# COMPUTE_CLUSTER0_MSMC_ECC_AGGR1_MSMC_ECC_AGGR1 register map
Vendor: Texas Instruments
Peripheral module from a debugger description file (folder J721S2).
Registers are 32-bit, access not given, reset 0x0 unless marked. A register's access mark holds for its fields unless they carry their own. Offsets are as the file gives them; lines under a group give offsets from that group; [hi:lo] are bit positions; {n}, {i} and the like mark numbered series; 'fields as' and 'values as' point back to an identical list; <NAME> marks a mode.

## COMPUTE_CLUSTER0_MSMC_ECC_AGGR1_MSMC_ECC_AGGR1
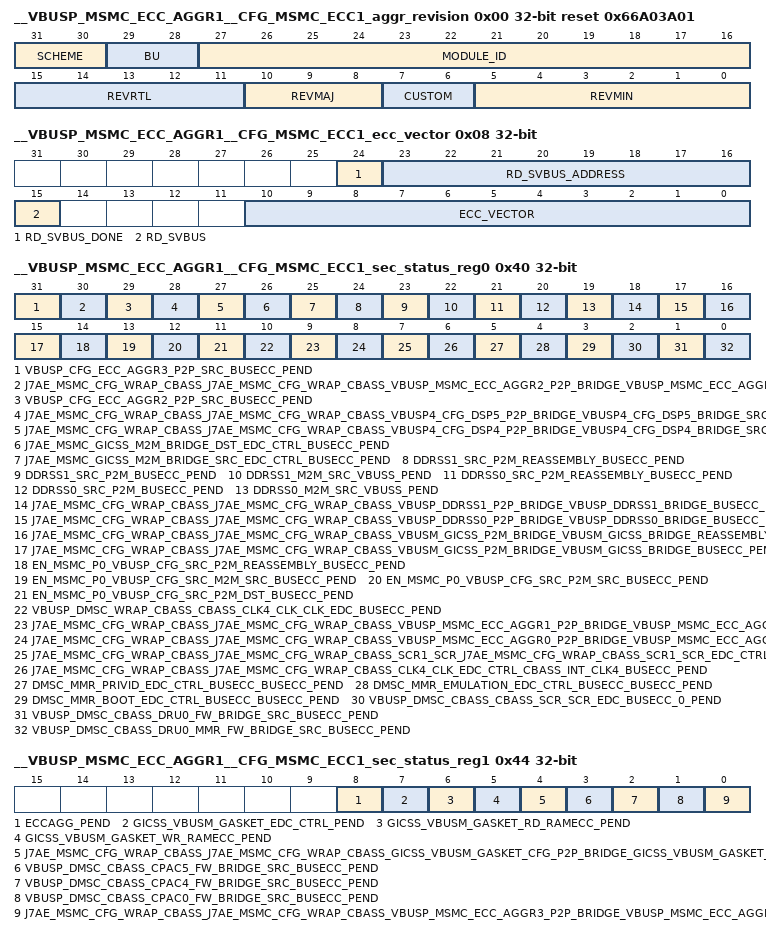
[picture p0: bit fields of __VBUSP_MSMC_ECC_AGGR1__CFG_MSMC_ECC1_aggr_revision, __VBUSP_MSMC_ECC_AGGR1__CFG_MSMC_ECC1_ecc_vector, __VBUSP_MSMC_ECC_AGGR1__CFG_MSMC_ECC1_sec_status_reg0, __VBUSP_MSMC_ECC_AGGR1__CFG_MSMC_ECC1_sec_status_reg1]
0x00 __VBUSP_MSMC_ECC_AGGR1__CFG_MSMC_ECC1_aggr_revision ro reset 0x66A03A01 — Revision parameters
  [31:30] SCHEME
  [29:28] BU
  [27:16] MODULE_ID
  [15:11] REVRTL — RTL version
  [10:8] REVMAJ — Major version
  [7:6] CUSTOM — Custom version
  [5:0] REVMIN — Minor version
0x08 __VBUSP_MSMC_ECC_AGGR1__CFG_MSMC_ECC1_ecc_vector — ECC Vector Register
  [24] RD_SVBUS_DONE — Status to indicate if read on serial VBUS is complete, write of any value will clear this bit. (access R/W1TC)
  [23:16] RD_SVBUS_ADDRESS rw — Read address
  [15] RD_SVBUS — Write 1 to trigger a read on the serial VBUS (access R/W1TS)
  [10:0] ECC_VECTOR rw — Value written to select the corresponding ECC RAM for control or status
0x0C __VBUSP_MSMC_ECC_AGGR1__CFG_MSMC_ECC1_misc_status ro reset 0x29 — Misc Status
  [10:0] NUM_RAMS — Indicates the number of RAMS serviced by the ECC aggregator
0x10 __VBUSP_MSMC_ECC_AGGR1__CFG_MSMC_ECC1_reserved_svbus rw — Reference other documents that contain the ECC RAM wrapper and EDC controller serial vbus register sets.
  [31:0] DATA — Serial VBUS register data
0x3C __VBUSP_MSMC_ECC_AGGR1__CFG_MSMC_ECC1_sec_eoi_reg — EOI Register
  [0] EOI_WR — EOI Register (access R/W1TS)
0x40 __VBUSP_MSMC_ECC_AGGR1__CFG_MSMC_ECC1_sec_status_reg0 — Interrupt Status Register 0
  [31] VBUSP_CFG_ECC_AGGR3_P2P_SRC_BUSECC_PEND — Interrupt Pending Status for vbusp_cfg_ecc_aggr3_p2p_src_busecc_pend (access R/W1TS)
  [30] J7AE_MSMC_CFG_WRAP_CBASS_J7AE_MSMC_CFG_WRAP_CBASS_VBUSP_MSMC_ECC_AGGR2_P2P_BRIDGE_VBUSP_MSMC_ECC_AGGR2_BRIDGE_BUSECC_PEND — Interrupt Pending Status for j7ae_msmc_cfg_wrap_cbass_j7ae_msmc_cfg_wrap_cbass_vbusp_msmc_ecc_aggr2_p2p_bridge_vbusp_msmc_ecc_aggr2_bridge_busecc_pend (access R/W1TS)
  [29] VBUSP_CFG_ECC_AGGR2_P2P_SRC_BUSECC_PEND — Interrupt Pending Status for vbusp_cfg_ecc_aggr2_p2p_src_busecc_pend (access R/W1TS)
  [28] J7AE_MSMC_CFG_WRAP_CBASS_J7AE_MSMC_CFG_WRAP_CBASS_VBUSP4_CFG_DSP5_P2P_BRIDGE_VBUSP4_CFG_DSP5_BRIDGE_SRC_BUSECC_PEND — Interrupt Pending Status for j7ae_msmc_cfg_wrap_cbass_j7ae_msmc_cfg_wrap_cbass_vbusp4_cfg_dsp5_p2p_bridge_vbusp4_cfg_dsp5_bridge_src_busecc_pend (access R/W1TS)
  [27] J7AE_MSMC_CFG_WRAP_CBASS_J7AE_MSMC_CFG_WRAP_CBASS_VBUSP4_CFG_DSP4_P2P_BRIDGE_VBUSP4_CFG_DSP4_BRIDGE_SRC_BUSECC_PEND — Interrupt Pending Status for j7ae_msmc_cfg_wrap_cbass_j7ae_msmc_cfg_wrap_cbass_vbusp4_cfg_dsp4_p2p_bridge_vbusp4_cfg_dsp4_bridge_src_busecc_pend (access R/W1TS)
  [26] J7AE_MSMC_GICSS_M2M_BRIDGE_DST_EDC_CTRL_BUSECC_PEND — Interrupt Pending Status for j7ae_msmc_gicss_m2m_bridge_dst_edc_ctrl_busecc_pend (access R/W1TS)
  [25] J7AE_MSMC_GICSS_M2M_BRIDGE_SRC_EDC_CTRL_BUSECC_PEND — Interrupt Pending Status for j7ae_msmc_gicss_m2m_bridge_src_edc_ctrl_busecc_pend (access R/W1TS)
  [24] DDRSS1_SRC_P2M_REASSEMBLY_BUSECC_PEND — Interrupt Pending Status for ddrss1_src_p2m_reassembly_busecc_pend (access R/W1TS)
  [23] DDRSS1_SRC_P2M_BUSECC_PEND — Interrupt Pending Status for ddrss1_src_p2m_busecc_pend (access R/W1TS)
  [22] DDRSS1_M2M_SRC_VBUSS_PEND — Interrupt Pending Status for ddrss1_m2m_src_vbuss_pend (access R/W1TS)
  [21] DDRSS0_SRC_P2M_REASSEMBLY_BUSECC_PEND — Interrupt Pending Status for ddrss0_src_p2m_reassembly_busecc_pend (access R/W1TS)
  [20] DDRSS0_SRC_P2M_BUSECC_PEND — Interrupt Pending Status for ddrss0_src_p2m_busecc_pend (access R/W1TS)
  [19] DDRSS0_M2M_SRC_VBUSS_PEND — Interrupt Pending Status for ddrss0_m2m_src_vbuss_pend (access R/W1TS)
  [18] J7AE_MSMC_CFG_WRAP_CBASS_J7AE_MSMC_CFG_WRAP_CBASS_VBUSP_DDRSS1_P2P_BRIDGE_VBUSP_DDRSS1_BRIDGE_BUSECC_PEND — Interrupt Pending Status for j7ae_msmc_cfg_wrap_cbass_j7ae_msmc_cfg_wrap_cbass_vbusp_ddrss1_p2p_bridge_vbusp_ddrss1_bridge_busecc_pend (access R/W1TS)
  [17] J7AE_MSMC_CFG_WRAP_CBASS_J7AE_MSMC_CFG_WRAP_CBASS_VBUSP_DDRSS0_P2P_BRIDGE_VBUSP_DDRSS0_BRIDGE_BUSECC_PEND — Interrupt Pending Status for j7ae_msmc_cfg_wrap_cbass_j7ae_msmc_cfg_wrap_cbass_vbusp_ddrss0_p2p_bridge_vbusp_ddrss0_bridge_busecc_pend (access R/W1TS)
  [16] J7AE_MSMC_CFG_WRAP_CBASS_J7AE_MSMC_CFG_WRAP_CBASS_VBUSM_GICSS_P2M_BRIDGE_VBUSM_GICSS_BRIDGE_REASSEMBLY_BUSECC_PEND — Interrupt Pending Status for j7ae_msmc_cfg_wrap_cbass_j7ae_msmc_cfg_wrap_cbass_vbusm_gicss_p2m_bridge_vbusm_gicss_bridge_reassembly_busecc_pend (access R/W1TS)
  [15] J7AE_MSMC_CFG_WRAP_CBASS_J7AE_MSMC_CFG_WRAP_CBASS_VBUSM_GICSS_P2M_BRIDGE_VBUSM_GICSS_BRIDGE_BUSECC_PEND — Interrupt Pending Status for j7ae_msmc_cfg_wrap_cbass_j7ae_msmc_cfg_wrap_cbass_vbusm_gicss_p2m_bridge_vbusm_gicss_bridge_busecc_pend (access R/W1TS)
  [14] EN_MSMC_P0_VBUSP_CFG_SRC_P2M_REASSEMBLY_BUSECC_PEND — Interrupt Pending Status for en_msmc_p0_vbusp_cfg_src_p2m_reassembly_busecc_pend (access R/W1TS)
  [13] EN_MSMC_P0_VBUSP_CFG_SRC_M2M_SRC_BUSECC_PEND — Interrupt Pending Status for en_msmc_p0_vbusp_cfg_src_m2m_src_busecc_pend (access R/W1TS)
  [12] EN_MSMC_P0_VBUSP_CFG_SRC_P2M_SRC_BUSECC_PEND — Interrupt Pending Status for en_msmc_p0_vbusp_cfg_src_p2m_src_busecc_pend (access R/W1TS)
  [11] EN_MSMC_P0_VBUSP_CFG_SRC_P2M_DST_BUSECC_PEND — Interrupt Pending Status for en_msmc_p0_vbusp_cfg_src_p2m_dst_busecc_pend (access R/W1TS)
  [10] VBUSP_DMSC_WRAP_CBASS_CBASS_CLK4_CLK_CLK_EDC_BUSECC_PEND — Interrupt Pending Status for vbusp_dmsc_wrap_cbass_cbass_clk4_clk_clk_edc_busecc_pend (access R/W1TS)
  [9] J7AE_MSMC_CFG_WRAP_CBASS_J7AE_MSMC_CFG_WRAP_CBASS_VBUSP_MSMC_ECC_AGGR1_P2P_BRIDGE_VBUSP_MSMC_ECC_AGGR1_BRIDGE_BUSECC_PEND — Interrupt Pending Status for j7ae_msmc_cfg_wrap_cbass_j7ae_msmc_cfg_wrap_cbass_vbusp_msmc_ecc_aggr1_p2p_bridge_vbusp_msmc_ecc_aggr1_bridge_busecc_pend (access R/W1TS)
  [8] J7AE_MSMC_CFG_WRAP_CBASS_J7AE_MSMC_CFG_WRAP_CBASS_VBUSP_MSMC_ECC_AGGR0_P2P_BRIDGE_VBUSP_MSMC_ECC_AGGR0_BRIDGE_SRC_BUSECC_PEND — Interrupt Pending Status for j7ae_msmc_cfg_wrap_cbass_j7ae_msmc_cfg_wrap_cbass_vbusp_msmc_ecc_aggr0_p2p_bridge_vbusp_msmc_ecc_aggr0_bridge_src_busecc_pend (access R/W1TS)
  [7] J7AE_MSMC_CFG_WRAP_CBASS_J7AE_MSMC_CFG_WRAP_CBASS_SCR1_SCR_J7AE_MSMC_CFG_WRAP_CBASS_SCR1_SCR_EDC_CTRL_BUSECC_PEND — Interrupt Pending Status for j7ae_msmc_cfg_wrap_cbass_j7ae_msmc_cfg_wrap_cbass_scr1_scr_j7ae_msmc_cfg_wrap_cbass_scr1_scr_edc_ctrl_busecc_pend (access R/W1TS)
  [6] J7AE_MSMC_CFG_WRAP_CBASS_J7AE_MSMC_CFG_WRAP_CBASS_CLK4_CLK_EDC_CTRL_CBASS_INT_CLK4_BUSECC_PEND — Interrupt Pending Status for j7ae_msmc_cfg_wrap_cbass_j7ae_msmc_cfg_wrap_cbass_clk4_clk_edc_ctrl_cbass_int_clk4_busecc_pend (access R/W1TS)
  [5] DMSC_MMR_PRIVID_EDC_CTRL_BUSECC_BUSECC_PEND — Interrupt Pending Status for dmsc_mmr_privid_edc_ctrl_busecc_busecc_pend (access R/W1TS)
  [4] DMSC_MMR_EMULATION_EDC_CTRL_BUSECC_BUSECC_PEND — Interrupt Pending Status for dmsc_mmr_emulation_edc_ctrl_busecc_busecc_pend (access R/W1TS)
  [3] DMSC_MMR_BOOT_EDC_CTRL_BUSECC_BUSECC_PEND — Interrupt Pending Status for dmsc_mmr_boot_edc_ctrl_busecc_busecc_pend (access R/W1TS)
  [2] VBUSP_DMSC_CBASS_CBASS_SCR_SCR_EDC_BUSECC_0_PEND — Interrupt Pending Status for vbusp_dmsc_cbass_cbass_scr_scr_edc_busecc_0_pend (access R/W1TS)
  [1] VBUSP_DMSC_CBASS_DRU0_FW_BRIDGE_SRC_BUSECC_PEND — Interrupt Pending Status for vbusp_dmsc_cbass_dru0_fw_bridge_src_busecc_pend (access R/W1TS)
  [0] VBUSP_DMSC_CBASS_DRU0_MMR_FW_BRIDGE_SRC_BUSECC_PEND — Interrupt Pending Status for vbusp_dmsc_cbass_dru0_mmr_fw_bridge_src_busecc_pend (access R/W1TS)
0x44 __VBUSP_MSMC_ECC_AGGR1__CFG_MSMC_ECC1_sec_status_reg1 — Interrupt Status Register 1
  [8] ECCAGG_PEND — Interrupt Pending Status for eccagg_pend (access R/W1TS)
  [7] GICSS_VBUSM_GASKET_EDC_CTRL_PEND — Interrupt Pending Status for gicss_vbusm_gasket_edc_ctrl_pend (access R/W1TS)
  [6] GICSS_VBUSM_GASKET_RD_RAMECC_PEND — Interrupt Pending Status for gicss_vbusm_gasket_rd_ramecc_pend (access R/W1TS)
  [5] GICSS_VBUSM_GASKET_WR_RAMECC_PEND — Interrupt Pending Status for gicss_vbusm_gasket_wr_ramecc_pend (access R/W1TS)
  [4] J7AE_MSMC_CFG_WRAP_CBASS_J7AE_MSMC_CFG_WRAP_CBASS_GICSS_VBUSM_GASKET_CFG_P2P_BRIDGE_GICSS_VBUSM_GASKET_CFG_BRIDGE_BUSECC_PEND — Interrupt Pending Status for j7ae_msmc_cfg_wrap_cbass_j7ae_msmc_cfg_wrap_cbass_gicss_vbusm_gasket_cfg_p2p_bridge_gicss_vbusm_gasket_cfg_bridge_busecc_pend (access R/W1TS)
  [3] VBUSP_DMSC_CBASS_CPAC5_FW_BRIDGE_SRC_BUSECC_PEND — Interrupt Pending Status for vbusp_dmsc_cbass_cpac5_fw_bridge_src_busecc_pend (access R/W1TS)
  [2] VBUSP_DMSC_CBASS_CPAC4_FW_BRIDGE_SRC_BUSECC_PEND — Interrupt Pending Status for vbusp_dmsc_cbass_cpac4_fw_bridge_src_busecc_pend (access R/W1TS)
  [1] VBUSP_DMSC_CBASS_CPAC0_FW_BRIDGE_SRC_BUSECC_PEND — Interrupt Pending Status for vbusp_dmsc_cbass_cpac0_fw_bridge_src_busecc_pend (access R/W1TS)
  [0] J7AE_MSMC_CFG_WRAP_CBASS_J7AE_MSMC_CFG_WRAP_CBASS_VBUSP_MSMC_ECC_AGGR3_P2P_BRIDGE_VBUSP_MSMC_ECC_AGGR3_BRIDGE_BUSECC_PEND — Interrupt Pending Status for j7ae_msmc_cfg_wrap_cbass_j7ae_msmc_cfg_wrap_cbass_vbusp_msmc_ecc_aggr3_p2p_bridge_vbusp_msmc_ecc_aggr3_bridge_busecc_pend (access R/W1TS)
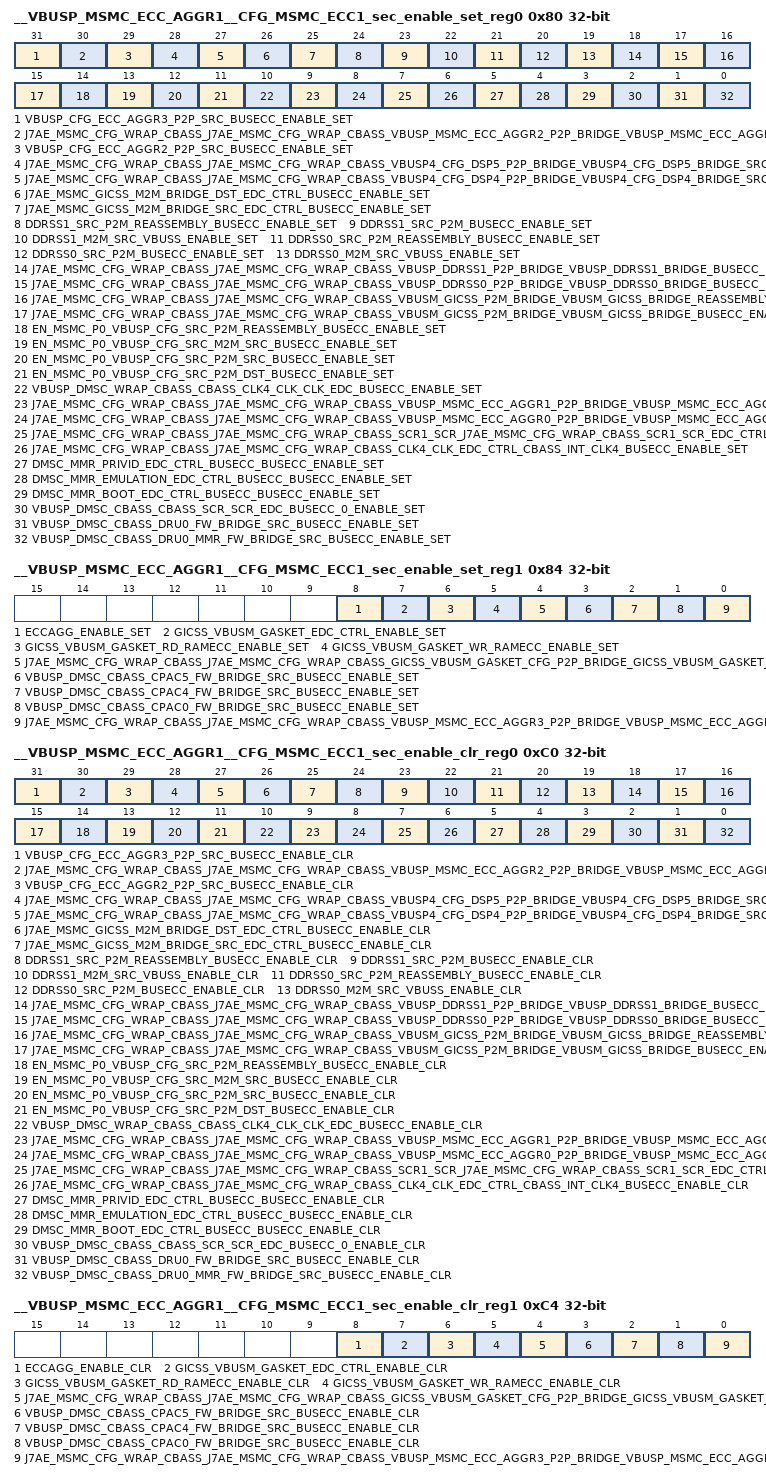
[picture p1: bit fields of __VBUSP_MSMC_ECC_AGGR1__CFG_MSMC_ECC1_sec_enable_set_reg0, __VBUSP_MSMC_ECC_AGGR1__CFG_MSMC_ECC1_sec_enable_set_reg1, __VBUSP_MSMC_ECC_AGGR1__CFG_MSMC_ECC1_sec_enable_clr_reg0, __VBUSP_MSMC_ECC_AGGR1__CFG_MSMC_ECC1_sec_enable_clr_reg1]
0x80 __VBUSP_MSMC_ECC_AGGR1__CFG_MSMC_ECC1_sec_enable_set_reg0 — Interrupt Enable Set Register 0
  [31] VBUSP_CFG_ECC_AGGR3_P2P_SRC_BUSECC_ENABLE_SET — Interrupt Enable Set Register for vbusp_cfg_ecc_aggr3_p2p_src_busecc_pend (access R/W1TS)
  [30] J7AE_MSMC_CFG_WRAP_CBASS_J7AE_MSMC_CFG_WRAP_CBASS_VBUSP_MSMC_ECC_AGGR2_P2P_BRIDGE_VBUSP_MSMC_ECC_AGGR2_BRIDGE_BUSECC_ENABLE_SET — Interrupt Enable Set Register for j7ae_msmc_cfg_wrap_cbass_j7ae_msmc_cfg_wrap_cbass_vbusp_msmc_ecc_aggr2_p2p_bridge_vbusp_msmc_ecc_aggr2_bridge_busecc_pend (access R/W1TS)
  [29] VBUSP_CFG_ECC_AGGR2_P2P_SRC_BUSECC_ENABLE_SET — Interrupt Enable Set Register for vbusp_cfg_ecc_aggr2_p2p_src_busecc_pend (access R/W1TS)
  [28] J7AE_MSMC_CFG_WRAP_CBASS_J7AE_MSMC_CFG_WRAP_CBASS_VBUSP4_CFG_DSP5_P2P_BRIDGE_VBUSP4_CFG_DSP5_BRIDGE_SRC_BUSECC_ENABLE_SET — Interrupt Enable Set Register for j7ae_msmc_cfg_wrap_cbass_j7ae_msmc_cfg_wrap_cbass_vbusp4_cfg_dsp5_p2p_bridge_vbusp4_cfg_dsp5_bridge_src_busecc_pend (access R/W1TS)
  [27] J7AE_MSMC_CFG_WRAP_CBASS_J7AE_MSMC_CFG_WRAP_CBASS_VBUSP4_CFG_DSP4_P2P_BRIDGE_VBUSP4_CFG_DSP4_BRIDGE_SRC_BUSECC_ENABLE_SET — Interrupt Enable Set Register for j7ae_msmc_cfg_wrap_cbass_j7ae_msmc_cfg_wrap_cbass_vbusp4_cfg_dsp4_p2p_bridge_vbusp4_cfg_dsp4_bridge_src_busecc_pend (access R/W1TS)
  [26] J7AE_MSMC_GICSS_M2M_BRIDGE_DST_EDC_CTRL_BUSECC_ENABLE_SET — Interrupt Enable Set Register for j7ae_msmc_gicss_m2m_bridge_dst_edc_ctrl_busecc_pend (access R/W1TS)
  [25] J7AE_MSMC_GICSS_M2M_BRIDGE_SRC_EDC_CTRL_BUSECC_ENABLE_SET — Interrupt Enable Set Register for j7ae_msmc_gicss_m2m_bridge_src_edc_ctrl_busecc_pend (access R/W1TS)
  [24] DDRSS1_SRC_P2M_REASSEMBLY_BUSECC_ENABLE_SET — Interrupt Enable Set Register for ddrss1_src_p2m_reassembly_busecc_pend (access R/W1TS)
  [23] DDRSS1_SRC_P2M_BUSECC_ENABLE_SET — Interrupt Enable Set Register for ddrss1_src_p2m_busecc_pend (access R/W1TS)
  [22] DDRSS1_M2M_SRC_VBUSS_ENABLE_SET — Interrupt Enable Set Register for ddrss1_m2m_src_vbuss_pend (access R/W1TS)
  [21] DDRSS0_SRC_P2M_REASSEMBLY_BUSECC_ENABLE_SET — Interrupt Enable Set Register for ddrss0_src_p2m_reassembly_busecc_pend (access R/W1TS)
  [20] DDRSS0_SRC_P2M_BUSECC_ENABLE_SET — Interrupt Enable Set Register for ddrss0_src_p2m_busecc_pend (access R/W1TS)
  [19] DDRSS0_M2M_SRC_VBUSS_ENABLE_SET — Interrupt Enable Set Register for ddrss0_m2m_src_vbuss_pend (access R/W1TS)
  [18] J7AE_MSMC_CFG_WRAP_CBASS_J7AE_MSMC_CFG_WRAP_CBASS_VBUSP_DDRSS1_P2P_BRIDGE_VBUSP_DDRSS1_BRIDGE_BUSECC_ENABLE_SET — Interrupt Enable Set Register for j7ae_msmc_cfg_wrap_cbass_j7ae_msmc_cfg_wrap_cbass_vbusp_ddrss1_p2p_bridge_vbusp_ddrss1_bridge_busecc_pend (access R/W1TS)
  [17] J7AE_MSMC_CFG_WRAP_CBASS_J7AE_MSMC_CFG_WRAP_CBASS_VBUSP_DDRSS0_P2P_BRIDGE_VBUSP_DDRSS0_BRIDGE_BUSECC_ENABLE_SET — Interrupt Enable Set Register for j7ae_msmc_cfg_wrap_cbass_j7ae_msmc_cfg_wrap_cbass_vbusp_ddrss0_p2p_bridge_vbusp_ddrss0_bridge_busecc_pend (access R/W1TS)
  [16] J7AE_MSMC_CFG_WRAP_CBASS_J7AE_MSMC_CFG_WRAP_CBASS_VBUSM_GICSS_P2M_BRIDGE_VBUSM_GICSS_BRIDGE_REASSEMBLY_BUSECC_ENABLE_SET — Interrupt Enable Set Register for j7ae_msmc_cfg_wrap_cbass_j7ae_msmc_cfg_wrap_cbass_vbusm_gicss_p2m_bridge_vbusm_gicss_bridge_reassembly_busecc_pend (access R/W1TS)
  [15] J7AE_MSMC_CFG_WRAP_CBASS_J7AE_MSMC_CFG_WRAP_CBASS_VBUSM_GICSS_P2M_BRIDGE_VBUSM_GICSS_BRIDGE_BUSECC_ENABLE_SET — Interrupt Enable Set Register for j7ae_msmc_cfg_wrap_cbass_j7ae_msmc_cfg_wrap_cbass_vbusm_gicss_p2m_bridge_vbusm_gicss_bridge_busecc_pend (access R/W1TS)
  [14] EN_MSMC_P0_VBUSP_CFG_SRC_P2M_REASSEMBLY_BUSECC_ENABLE_SET — Interrupt Enable Set Register for en_msmc_p0_vbusp_cfg_src_p2m_reassembly_busecc_pend (access R/W1TS)
  [13] EN_MSMC_P0_VBUSP_CFG_SRC_M2M_SRC_BUSECC_ENABLE_SET — Interrupt Enable Set Register for en_msmc_p0_vbusp_cfg_src_m2m_src_busecc_pend (access R/W1TS)
  [12] EN_MSMC_P0_VBUSP_CFG_SRC_P2M_SRC_BUSECC_ENABLE_SET — Interrupt Enable Set Register for en_msmc_p0_vbusp_cfg_src_p2m_src_busecc_pend (access R/W1TS)
  [11] EN_MSMC_P0_VBUSP_CFG_SRC_P2M_DST_BUSECC_ENABLE_SET — Interrupt Enable Set Register for en_msmc_p0_vbusp_cfg_src_p2m_dst_busecc_pend (access R/W1TS)
  [10] VBUSP_DMSC_WRAP_CBASS_CBASS_CLK4_CLK_CLK_EDC_BUSECC_ENABLE_SET — Interrupt Enable Set Register for vbusp_dmsc_wrap_cbass_cbass_clk4_clk_clk_edc_busecc_pend (access R/W1TS)
  [9] J7AE_MSMC_CFG_WRAP_CBASS_J7AE_MSMC_CFG_WRAP_CBASS_VBUSP_MSMC_ECC_AGGR1_P2P_BRIDGE_VBUSP_MSMC_ECC_AGGR1_BRIDGE_BUSECC_ENABLE_SET — Interrupt Enable Set Register for j7ae_msmc_cfg_wrap_cbass_j7ae_msmc_cfg_wrap_cbass_vbusp_msmc_ecc_aggr1_p2p_bridge_vbusp_msmc_ecc_aggr1_bridge_busecc_pend (access R/W1TS)
  [8] J7AE_MSMC_CFG_WRAP_CBASS_J7AE_MSMC_CFG_WRAP_CBASS_VBUSP_MSMC_ECC_AGGR0_P2P_BRIDGE_VBUSP_MSMC_ECC_AGGR0_BRIDGE_SRC_BUSECC_ENABLE_SET — Interrupt Enable Set Register for j7ae_msmc_cfg_wrap_cbass_j7ae_msmc_cfg_wrap_cbass_vbusp_msmc_ecc_aggr0_p2p_bridge_vbusp_msmc_ecc_aggr0_bridge_src_busecc_pend (access R/W1TS)
  [7] J7AE_MSMC_CFG_WRAP_CBASS_J7AE_MSMC_CFG_WRAP_CBASS_SCR1_SCR_J7AE_MSMC_CFG_WRAP_CBASS_SCR1_SCR_EDC_CTRL_BUSECC_ENABLE_SET — Interrupt Enable Set Register for j7ae_msmc_cfg_wrap_cbass_j7ae_msmc_cfg_wrap_cbass_scr1_scr_j7ae_msmc_cfg_wrap_cbass_scr1_scr_edc_ctrl_busecc_pend (access R/W1TS)
  [6] J7AE_MSMC_CFG_WRAP_CBASS_J7AE_MSMC_CFG_WRAP_CBASS_CLK4_CLK_EDC_CTRL_CBASS_INT_CLK4_BUSECC_ENABLE_SET — Interrupt Enable Set Register for j7ae_msmc_cfg_wrap_cbass_j7ae_msmc_cfg_wrap_cbass_clk4_clk_edc_ctrl_cbass_int_clk4_busecc_pend (access R/W1TS)
  [5] DMSC_MMR_PRIVID_EDC_CTRL_BUSECC_BUSECC_ENABLE_SET — Interrupt Enable Set Register for dmsc_mmr_privid_edc_ctrl_busecc_busecc_pend (access R/W1TS)
  [4] DMSC_MMR_EMULATION_EDC_CTRL_BUSECC_BUSECC_ENABLE_SET — Interrupt Enable Set Register for dmsc_mmr_emulation_edc_ctrl_busecc_busecc_pend (access R/W1TS)
  [3] DMSC_MMR_BOOT_EDC_CTRL_BUSECC_BUSECC_ENABLE_SET — Interrupt Enable Set Register for dmsc_mmr_boot_edc_ctrl_busecc_busecc_pend (access R/W1TS)
  [2] VBUSP_DMSC_CBASS_CBASS_SCR_SCR_EDC_BUSECC_0_ENABLE_SET — Interrupt Enable Set Register for vbusp_dmsc_cbass_cbass_scr_scr_edc_busecc_0_pend (access R/W1TS)
  [1] VBUSP_DMSC_CBASS_DRU0_FW_BRIDGE_SRC_BUSECC_ENABLE_SET — Interrupt Enable Set Register for vbusp_dmsc_cbass_dru0_fw_bridge_src_busecc_pend (access R/W1TS)
  [0] VBUSP_DMSC_CBASS_DRU0_MMR_FW_BRIDGE_SRC_BUSECC_ENABLE_SET — Interrupt Enable Set Register for vbusp_dmsc_cbass_dru0_mmr_fw_bridge_src_busecc_pend (access R/W1TS)
0x84 __VBUSP_MSMC_ECC_AGGR1__CFG_MSMC_ECC1_sec_enable_set_reg1 — Interrupt Enable Set Register 1
  [8] ECCAGG_ENABLE_SET — Interrupt Enable Set Register for eccagg_pend (access R/W1TS)
  [7] GICSS_VBUSM_GASKET_EDC_CTRL_ENABLE_SET — Interrupt Enable Set Register for gicss_vbusm_gasket_edc_ctrl_pend (access R/W1TS)
  [6] GICSS_VBUSM_GASKET_RD_RAMECC_ENABLE_SET — Interrupt Enable Set Register for gicss_vbusm_gasket_rd_ramecc_pend (access R/W1TS)
  [5] GICSS_VBUSM_GASKET_WR_RAMECC_ENABLE_SET — Interrupt Enable Set Register for gicss_vbusm_gasket_wr_ramecc_pend (access R/W1TS)
  [4] J7AE_MSMC_CFG_WRAP_CBASS_J7AE_MSMC_CFG_WRAP_CBASS_GICSS_VBUSM_GASKET_CFG_P2P_BRIDGE_GICSS_VBUSM_GASKET_CFG_BRIDGE_BUSECC_ENABLE_SET — Interrupt Enable Set Register for j7ae_msmc_cfg_wrap_cbass_j7ae_msmc_cfg_wrap_cbass_gicss_vbusm_gasket_cfg_p2p_bridge_gicss_vbusm_gasket_cfg_bridge_busecc_pend (access R/W1TS)
  [3] VBUSP_DMSC_CBASS_CPAC5_FW_BRIDGE_SRC_BUSECC_ENABLE_SET — Interrupt Enable Set Register for vbusp_dmsc_cbass_cpac5_fw_bridge_src_busecc_pend (access R/W1TS)
  [2] VBUSP_DMSC_CBASS_CPAC4_FW_BRIDGE_SRC_BUSECC_ENABLE_SET — Interrupt Enable Set Register for vbusp_dmsc_cbass_cpac4_fw_bridge_src_busecc_pend (access R/W1TS)
  [1] VBUSP_DMSC_CBASS_CPAC0_FW_BRIDGE_SRC_BUSECC_ENABLE_SET — Interrupt Enable Set Register for vbusp_dmsc_cbass_cpac0_fw_bridge_src_busecc_pend (access R/W1TS)
  [0] J7AE_MSMC_CFG_WRAP_CBASS_J7AE_MSMC_CFG_WRAP_CBASS_VBUSP_MSMC_ECC_AGGR3_P2P_BRIDGE_VBUSP_MSMC_ECC_AGGR3_BRIDGE_BUSECC_ENABLE_SET — Interrupt Enable Set Register for j7ae_msmc_cfg_wrap_cbass_j7ae_msmc_cfg_wrap_cbass_vbusp_msmc_ecc_aggr3_p2p_bridge_vbusp_msmc_ecc_aggr3_bridge_busecc_pend (access R/W1TS)
0xC0 __VBUSP_MSMC_ECC_AGGR1__CFG_MSMC_ECC1_sec_enable_clr_reg0 — Interrupt Enable Clear Register 0
  [31] VBUSP_CFG_ECC_AGGR3_P2P_SRC_BUSECC_ENABLE_CLR — Interrupt Enable Clear Register for vbusp_cfg_ecc_aggr3_p2p_src_busecc_pend (access R/W1TC)
  [30] J7AE_MSMC_CFG_WRAP_CBASS_J7AE_MSMC_CFG_WRAP_CBASS_VBUSP_MSMC_ECC_AGGR2_P2P_BRIDGE_VBUSP_MSMC_ECC_AGGR2_BRIDGE_BUSECC_ENABLE_CLR — Interrupt Enable Clear Register for j7ae_msmc_cfg_wrap_cbass_j7ae_msmc_cfg_wrap_cbass_vbusp_msmc_ecc_aggr2_p2p_bridge_vbusp_msmc_ecc_aggr2_bridge_busecc_pend (access R/W1TC)
  [29] VBUSP_CFG_ECC_AGGR2_P2P_SRC_BUSECC_ENABLE_CLR — Interrupt Enable Clear Register for vbusp_cfg_ecc_aggr2_p2p_src_busecc_pend (access R/W1TC)
  [28] J7AE_MSMC_CFG_WRAP_CBASS_J7AE_MSMC_CFG_WRAP_CBASS_VBUSP4_CFG_DSP5_P2P_BRIDGE_VBUSP4_CFG_DSP5_BRIDGE_SRC_BUSECC_ENABLE_CLR — Interrupt Enable Clear Register for j7ae_msmc_cfg_wrap_cbass_j7ae_msmc_cfg_wrap_cbass_vbusp4_cfg_dsp5_p2p_bridge_vbusp4_cfg_dsp5_bridge_src_busecc_pend (access R/W1TC)
  [27] J7AE_MSMC_CFG_WRAP_CBASS_J7AE_MSMC_CFG_WRAP_CBASS_VBUSP4_CFG_DSP4_P2P_BRIDGE_VBUSP4_CFG_DSP4_BRIDGE_SRC_BUSECC_ENABLE_CLR — Interrupt Enable Clear Register for j7ae_msmc_cfg_wrap_cbass_j7ae_msmc_cfg_wrap_cbass_vbusp4_cfg_dsp4_p2p_bridge_vbusp4_cfg_dsp4_bridge_src_busecc_pend (access R/W1TC)
  [26] J7AE_MSMC_GICSS_M2M_BRIDGE_DST_EDC_CTRL_BUSECC_ENABLE_CLR — Interrupt Enable Clear Register for j7ae_msmc_gicss_m2m_bridge_dst_edc_ctrl_busecc_pend (access R/W1TC)
  [25] J7AE_MSMC_GICSS_M2M_BRIDGE_SRC_EDC_CTRL_BUSECC_ENABLE_CLR — Interrupt Enable Clear Register for j7ae_msmc_gicss_m2m_bridge_src_edc_ctrl_busecc_pend (access R/W1TC)
  [24] DDRSS1_SRC_P2M_REASSEMBLY_BUSECC_ENABLE_CLR — Interrupt Enable Clear Register for ddrss1_src_p2m_reassembly_busecc_pend (access R/W1TC)
  [23] DDRSS1_SRC_P2M_BUSECC_ENABLE_CLR — Interrupt Enable Clear Register for ddrss1_src_p2m_busecc_pend (access R/W1TC)
  [22] DDRSS1_M2M_SRC_VBUSS_ENABLE_CLR — Interrupt Enable Clear Register for ddrss1_m2m_src_vbuss_pend (access R/W1TC)
  [21] DDRSS0_SRC_P2M_REASSEMBLY_BUSECC_ENABLE_CLR — Interrupt Enable Clear Register for ddrss0_src_p2m_reassembly_busecc_pend (access R/W1TC)
  [20] DDRSS0_SRC_P2M_BUSECC_ENABLE_CLR — Interrupt Enable Clear Register for ddrss0_src_p2m_busecc_pend (access R/W1TC)
  [19] DDRSS0_M2M_SRC_VBUSS_ENABLE_CLR — Interrupt Enable Clear Register for ddrss0_m2m_src_vbuss_pend (access R/W1TC)
  [18] J7AE_MSMC_CFG_WRAP_CBASS_J7AE_MSMC_CFG_WRAP_CBASS_VBUSP_DDRSS1_P2P_BRIDGE_VBUSP_DDRSS1_BRIDGE_BUSECC_ENABLE_CLR — Interrupt Enable Clear Register for j7ae_msmc_cfg_wrap_cbass_j7ae_msmc_cfg_wrap_cbass_vbusp_ddrss1_p2p_bridge_vbusp_ddrss1_bridge_busecc_pend (access R/W1TC)
  [17] J7AE_MSMC_CFG_WRAP_CBASS_J7AE_MSMC_CFG_WRAP_CBASS_VBUSP_DDRSS0_P2P_BRIDGE_VBUSP_DDRSS0_BRIDGE_BUSECC_ENABLE_CLR — Interrupt Enable Clear Register for j7ae_msmc_cfg_wrap_cbass_j7ae_msmc_cfg_wrap_cbass_vbusp_ddrss0_p2p_bridge_vbusp_ddrss0_bridge_busecc_pend (access R/W1TC)
  [16] J7AE_MSMC_CFG_WRAP_CBASS_J7AE_MSMC_CFG_WRAP_CBASS_VBUSM_GICSS_P2M_BRIDGE_VBUSM_GICSS_BRIDGE_REASSEMBLY_BUSECC_ENABLE_CLR — Interrupt Enable Clear Register for j7ae_msmc_cfg_wrap_cbass_j7ae_msmc_cfg_wrap_cbass_vbusm_gicss_p2m_bridge_vbusm_gicss_bridge_reassembly_busecc_pend (access R/W1TC)
  [15] J7AE_MSMC_CFG_WRAP_CBASS_J7AE_MSMC_CFG_WRAP_CBASS_VBUSM_GICSS_P2M_BRIDGE_VBUSM_GICSS_BRIDGE_BUSECC_ENABLE_CLR — Interrupt Enable Clear Register for j7ae_msmc_cfg_wrap_cbass_j7ae_msmc_cfg_wrap_cbass_vbusm_gicss_p2m_bridge_vbusm_gicss_bridge_busecc_pend (access R/W1TC)
  [14] EN_MSMC_P0_VBUSP_CFG_SRC_P2M_REASSEMBLY_BUSECC_ENABLE_CLR — Interrupt Enable Clear Register for en_msmc_p0_vbusp_cfg_src_p2m_reassembly_busecc_pend (access R/W1TC)
  [13] EN_MSMC_P0_VBUSP_CFG_SRC_M2M_SRC_BUSECC_ENABLE_CLR — Interrupt Enable Clear Register for en_msmc_p0_vbusp_cfg_src_m2m_src_busecc_pend (access R/W1TC)
  [12] EN_MSMC_P0_VBUSP_CFG_SRC_P2M_SRC_BUSECC_ENABLE_CLR — Interrupt Enable Clear Register for en_msmc_p0_vbusp_cfg_src_p2m_src_busecc_pend (access R/W1TC)
  [11] EN_MSMC_P0_VBUSP_CFG_SRC_P2M_DST_BUSECC_ENABLE_CLR — Interrupt Enable Clear Register for en_msmc_p0_vbusp_cfg_src_p2m_dst_busecc_pend (access R/W1TC)
  [10] VBUSP_DMSC_WRAP_CBASS_CBASS_CLK4_CLK_CLK_EDC_BUSECC_ENABLE_CLR — Interrupt Enable Clear Register for vbusp_dmsc_wrap_cbass_cbass_clk4_clk_clk_edc_busecc_pend (access R/W1TC)
  [9] J7AE_MSMC_CFG_WRAP_CBASS_J7AE_MSMC_CFG_WRAP_CBASS_VBUSP_MSMC_ECC_AGGR1_P2P_BRIDGE_VBUSP_MSMC_ECC_AGGR1_BRIDGE_BUSECC_ENABLE_CLR — Interrupt Enable Clear Register for j7ae_msmc_cfg_wrap_cbass_j7ae_msmc_cfg_wrap_cbass_vbusp_msmc_ecc_aggr1_p2p_bridge_vbusp_msmc_ecc_aggr1_bridge_busecc_pend (access R/W1TC)
  [8] J7AE_MSMC_CFG_WRAP_CBASS_J7AE_MSMC_CFG_WRAP_CBASS_VBUSP_MSMC_ECC_AGGR0_P2P_BRIDGE_VBUSP_MSMC_ECC_AGGR0_BRIDGE_SRC_BUSECC_ENABLE_CLR — Interrupt Enable Clear Register for j7ae_msmc_cfg_wrap_cbass_j7ae_msmc_cfg_wrap_cbass_vbusp_msmc_ecc_aggr0_p2p_bridge_vbusp_msmc_ecc_aggr0_bridge_src_busecc_pend (access R/W1TC)
  [7] J7AE_MSMC_CFG_WRAP_CBASS_J7AE_MSMC_CFG_WRAP_CBASS_SCR1_SCR_J7AE_MSMC_CFG_WRAP_CBASS_SCR1_SCR_EDC_CTRL_BUSECC_ENABLE_CLR — Interrupt Enable Clear Register for j7ae_msmc_cfg_wrap_cbass_j7ae_msmc_cfg_wrap_cbass_scr1_scr_j7ae_msmc_cfg_wrap_cbass_scr1_scr_edc_ctrl_busecc_pend (access R/W1TC)
  [6] J7AE_MSMC_CFG_WRAP_CBASS_J7AE_MSMC_CFG_WRAP_CBASS_CLK4_CLK_EDC_CTRL_CBASS_INT_CLK4_BUSECC_ENABLE_CLR — Interrupt Enable Clear Register for j7ae_msmc_cfg_wrap_cbass_j7ae_msmc_cfg_wrap_cbass_clk4_clk_edc_ctrl_cbass_int_clk4_busecc_pend (access R/W1TC)
  [5] DMSC_MMR_PRIVID_EDC_CTRL_BUSECC_BUSECC_ENABLE_CLR — Interrupt Enable Clear Register for dmsc_mmr_privid_edc_ctrl_busecc_busecc_pend (access R/W1TC)
  [4] DMSC_MMR_EMULATION_EDC_CTRL_BUSECC_BUSECC_ENABLE_CLR — Interrupt Enable Clear Register for dmsc_mmr_emulation_edc_ctrl_busecc_busecc_pend (access R/W1TC)
  [3] DMSC_MMR_BOOT_EDC_CTRL_BUSECC_BUSECC_ENABLE_CLR — Interrupt Enable Clear Register for dmsc_mmr_boot_edc_ctrl_busecc_busecc_pend (access R/W1TC)
  [2] VBUSP_DMSC_CBASS_CBASS_SCR_SCR_EDC_BUSECC_0_ENABLE_CLR — Interrupt Enable Clear Register for vbusp_dmsc_cbass_cbass_scr_scr_edc_busecc_0_pend (access R/W1TC)
  [1] VBUSP_DMSC_CBASS_DRU0_FW_BRIDGE_SRC_BUSECC_ENABLE_CLR — Interrupt Enable Clear Register for vbusp_dmsc_cbass_dru0_fw_bridge_src_busecc_pend (access R/W1TC)
  [0] VBUSP_DMSC_CBASS_DRU0_MMR_FW_BRIDGE_SRC_BUSECC_ENABLE_CLR — Interrupt Enable Clear Register for vbusp_dmsc_cbass_dru0_mmr_fw_bridge_src_busecc_pend (access R/W1TC)
0xC4 __VBUSP_MSMC_ECC_AGGR1__CFG_MSMC_ECC1_sec_enable_clr_reg1 — Interrupt Enable Clear Register 1
  [8] ECCAGG_ENABLE_CLR — Interrupt Enable Clear Register for eccagg_pend (access R/W1TC)
  [7] GICSS_VBUSM_GASKET_EDC_CTRL_ENABLE_CLR — Interrupt Enable Clear Register for gicss_vbusm_gasket_edc_ctrl_pend (access R/W1TC)
  [6] GICSS_VBUSM_GASKET_RD_RAMECC_ENABLE_CLR — Interrupt Enable Clear Register for gicss_vbusm_gasket_rd_ramecc_pend (access R/W1TC)
  [5] GICSS_VBUSM_GASKET_WR_RAMECC_ENABLE_CLR — Interrupt Enable Clear Register for gicss_vbusm_gasket_wr_ramecc_pend (access R/W1TC)
  [4] J7AE_MSMC_CFG_WRAP_CBASS_J7AE_MSMC_CFG_WRAP_CBASS_GICSS_VBUSM_GASKET_CFG_P2P_BRIDGE_GICSS_VBUSM_GASKET_CFG_BRIDGE_BUSECC_ENABLE_CLR — Interrupt Enable Clear Register for j7ae_msmc_cfg_wrap_cbass_j7ae_msmc_cfg_wrap_cbass_gicss_vbusm_gasket_cfg_p2p_bridge_gicss_vbusm_gasket_cfg_bridge_busecc_pend (access R/W1TC)
  [3] VBUSP_DMSC_CBASS_CPAC5_FW_BRIDGE_SRC_BUSECC_ENABLE_CLR — Interrupt Enable Clear Register for vbusp_dmsc_cbass_cpac5_fw_bridge_src_busecc_pend (access R/W1TC)
  [2] VBUSP_DMSC_CBASS_CPAC4_FW_BRIDGE_SRC_BUSECC_ENABLE_CLR — Interrupt Enable Clear Register for vbusp_dmsc_cbass_cpac4_fw_bridge_src_busecc_pend (access R/W1TC)
  [1] VBUSP_DMSC_CBASS_CPAC0_FW_BRIDGE_SRC_BUSECC_ENABLE_CLR — Interrupt Enable Clear Register for vbusp_dmsc_cbass_cpac0_fw_bridge_src_busecc_pend (access R/W1TC)
  [0] J7AE_MSMC_CFG_WRAP_CBASS_J7AE_MSMC_CFG_WRAP_CBASS_VBUSP_MSMC_ECC_AGGR3_P2P_BRIDGE_VBUSP_MSMC_ECC_AGGR3_BRIDGE_BUSECC_ENABLE_CLR — Interrupt Enable Clear Register for j7ae_msmc_cfg_wrap_cbass_j7ae_msmc_cfg_wrap_cbass_vbusp_msmc_ecc_aggr3_p2p_bridge_vbusp_msmc_ecc_aggr3_bridge_busecc_pend (access R/W1TC)
0x13C __VBUSP_MSMC_ECC_AGGR1__CFG_MSMC_ECC1_ded_eoi_reg — EOI Register
  [0] EOI_WR — EOI Register (access R/W1TS)
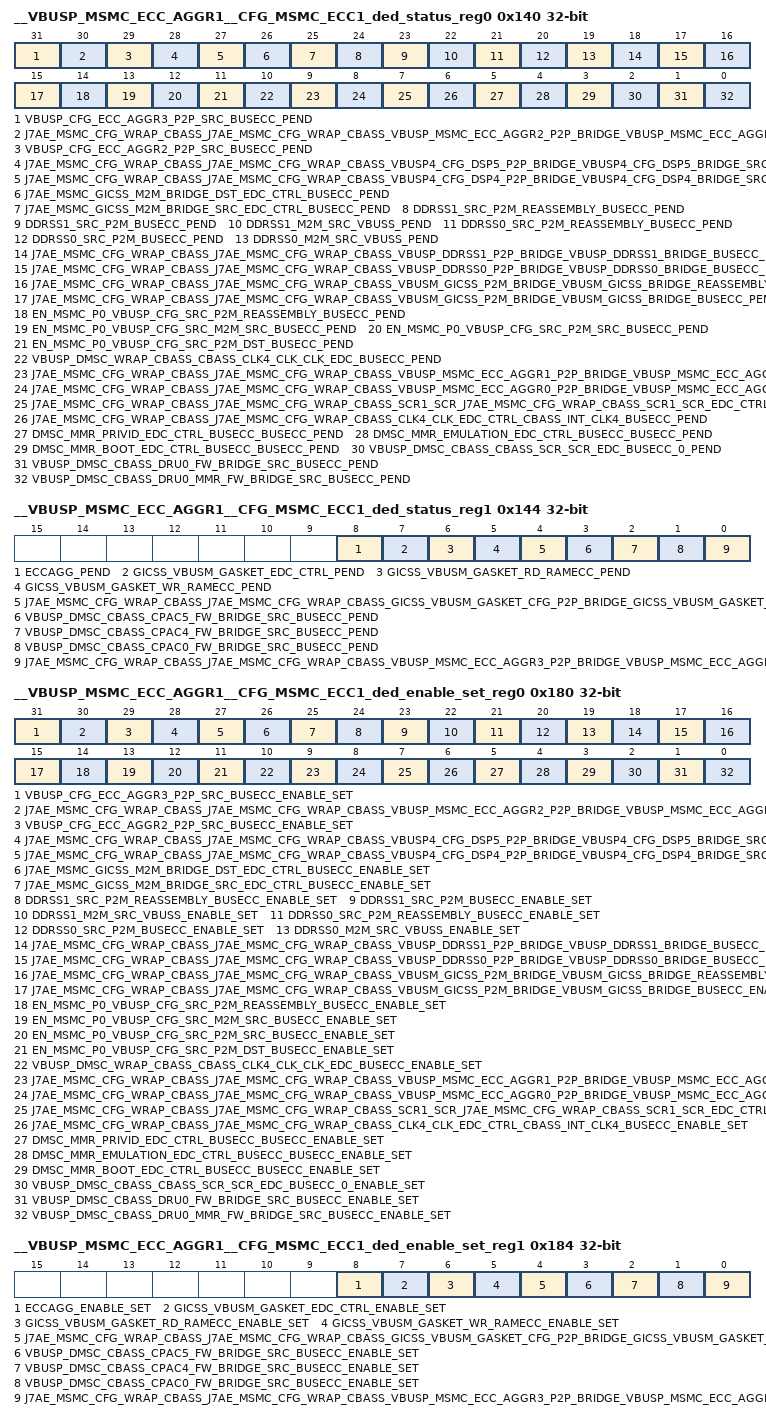
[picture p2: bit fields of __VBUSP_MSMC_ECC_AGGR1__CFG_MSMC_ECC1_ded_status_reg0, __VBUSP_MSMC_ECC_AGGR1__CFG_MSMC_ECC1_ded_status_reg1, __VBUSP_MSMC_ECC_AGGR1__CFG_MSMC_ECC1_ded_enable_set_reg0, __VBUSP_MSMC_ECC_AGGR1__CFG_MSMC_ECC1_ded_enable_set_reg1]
0x140 __VBUSP_MSMC_ECC_AGGR1__CFG_MSMC_ECC1_ded_status_reg0 — Interrupt Status Register 0
  fields as __VBUSP_MSMC_ECC_AGGR1__CFG_MSMC_ECC1_sec_status_reg0
0x144 __VBUSP_MSMC_ECC_AGGR1__CFG_MSMC_ECC1_ded_status_reg1 — Interrupt Status Register 1
  fields as __VBUSP_MSMC_ECC_AGGR1__CFG_MSMC_ECC1_sec_status_reg1
0x180 __VBUSP_MSMC_ECC_AGGR1__CFG_MSMC_ECC1_ded_enable_set_reg0 — Interrupt Enable Set Register 0
  fields as __VBUSP_MSMC_ECC_AGGR1__CFG_MSMC_ECC1_sec_enable_set_reg0
0x184 __VBUSP_MSMC_ECC_AGGR1__CFG_MSMC_ECC1_ded_enable_set_reg1 — Interrupt Enable Set Register 1
  fields as __VBUSP_MSMC_ECC_AGGR1__CFG_MSMC_ECC1_sec_enable_set_reg1
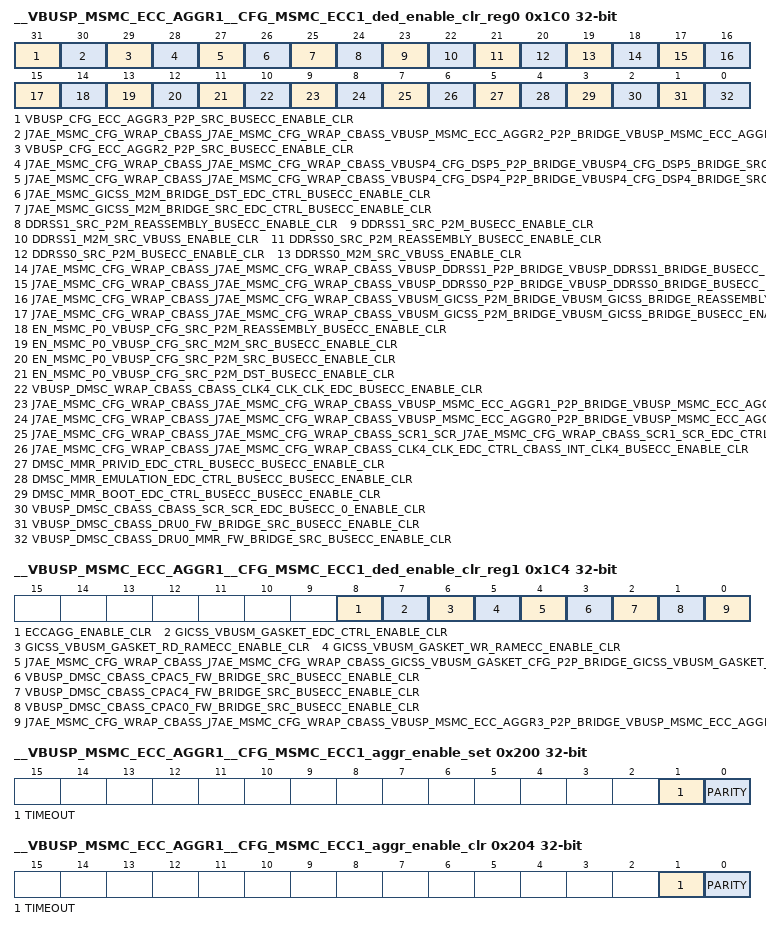
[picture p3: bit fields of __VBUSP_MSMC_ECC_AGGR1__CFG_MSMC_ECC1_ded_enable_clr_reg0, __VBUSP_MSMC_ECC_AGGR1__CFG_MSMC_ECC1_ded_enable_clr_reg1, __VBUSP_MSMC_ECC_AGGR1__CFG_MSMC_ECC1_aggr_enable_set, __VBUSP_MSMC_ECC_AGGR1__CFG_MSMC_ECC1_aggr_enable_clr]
0x1C0 __VBUSP_MSMC_ECC_AGGR1__CFG_MSMC_ECC1_ded_enable_clr_reg0 — Interrupt Enable Clear Register 0
  fields as __VBUSP_MSMC_ECC_AGGR1__CFG_MSMC_ECC1_sec_enable_clr_reg0
0x1C4 __VBUSP_MSMC_ECC_AGGR1__CFG_MSMC_ECC1_ded_enable_clr_reg1 — Interrupt Enable Clear Register 1
  fields as __VBUSP_MSMC_ECC_AGGR1__CFG_MSMC_ECC1_sec_enable_clr_reg1
0x200 __VBUSP_MSMC_ECC_AGGR1__CFG_MSMC_ECC1_aggr_enable_set — AGGR interrupt enable set Register
  [1] TIMEOUT — interrupt enable set for svbus timeout errors (access R/W1TS)
  [0] PARITY — interrupt enable set for parity errors (access R/W1TS)
0x204 __VBUSP_MSMC_ECC_AGGR1__CFG_MSMC_ECC1_aggr_enable_clr — AGGR interrupt enable clear Register
  [1] TIMEOUT — interrupt enable clear for svbus timeout errors (access R/W1TC)
  [0] PARITY — interrupt enable clear for parity errors (access R/W1TC)
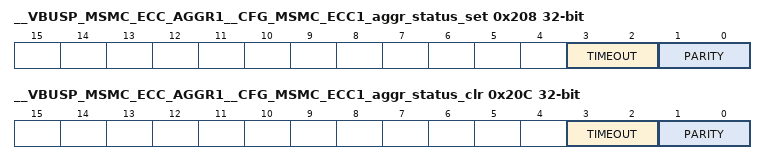
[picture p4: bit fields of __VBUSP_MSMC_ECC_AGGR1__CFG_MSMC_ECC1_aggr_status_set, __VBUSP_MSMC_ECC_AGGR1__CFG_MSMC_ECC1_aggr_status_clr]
0x208 __VBUSP_MSMC_ECC_AGGR1__CFG_MSMC_ECC1_aggr_status_set — AGGR interrupt status set Register
  [3:2] TIMEOUT — interrupt status set for svbus timeout errors (access R/WI)
  [1:0] PARITY — interrupt status set for parity errors (access R/WI)
0x20C __VBUSP_MSMC_ECC_AGGR1__CFG_MSMC_ECC1_aggr_status_clr — AGGR interrupt status clear Register
  [3:2] TIMEOUT — interrupt status clear for svbus timeout errors (access R/WD)
  [1:0] PARITY — interrupt status clear for parity errors (access R/WD)
